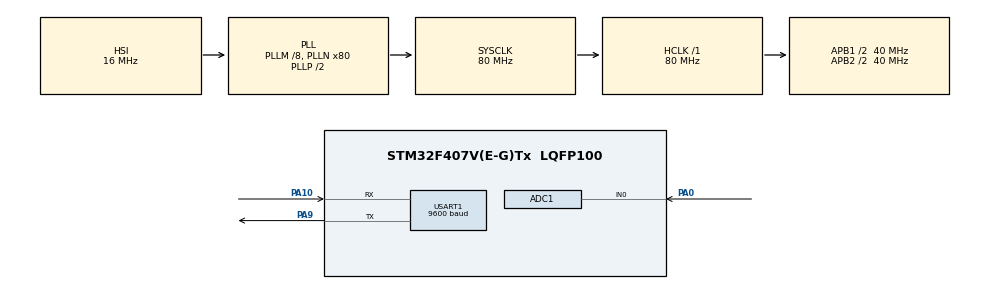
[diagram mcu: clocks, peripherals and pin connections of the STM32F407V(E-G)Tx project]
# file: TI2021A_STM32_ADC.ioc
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ADC1.Channel-0\#ChannelRegularConversion=ADC_CHANNEL_0
ADC1.ContinuousConvMode=ENABLE
ADC1.DMAContinuousRequests=ENABLE
ADC1.NbrOfConversionFlag=1
ADC1.Rank-0\#ChannelRegularConversion=1
ADC1.SamplingTime-0\#ChannelRegularConversion=ADC_SAMPLETIME_3CYCLES
ADC1.master=1
Dma.ADC1.0.Direction=DMA_PERIPH_TO_MEMORY
Dma.ADC1.0.FIFOMode=DMA_FIFOMODE_DISABLE
Dma.ADC1.0.Instance=DMA2_Stream0
Dma.ADC1.0.MemDataAlignment=DMA_MDATAALIGN_WORD
Dma.ADC1.0.MemInc=DMA_MINC_ENABLE
Dma.ADC1.0.Mode=DMA_CIRCULAR
Dma.ADC1.0.PeriphDataAlignment=DMA_PDATAALIGN_WORD
Dma.ADC1.0.PeriphInc=DMA_PINC_DISABLE
Dma.ADC1.0.Priority=DMA_PRIORITY_LOW
Dma.Request0=ADC1
Mcu.Family=STM32F4
Mcu.Name=STM32F407V(E-G)Tx
Mcu.Package=LQFP100
NVIC.DMA2_Stream0_IRQn=true\:0\:0\:false\:false\:true\:false\:true\:true
NVIC.PriorityGroup=NVIC_PRIORITYGROUP_4
NVIC.USART1_IRQn=true\:0\:0\:false\:false\:true\:true\:true\:true
PA0-WKUP.Signal=ADCx_IN0
PA10.Mode=Asynchronous
PA10.Signal=USART1_RX
PA13.Mode=Serial_Wire
PA13.Signal=SYS_JTMS-SWDIO
PA14.Mode=Serial_Wire
PA14.Signal=SYS_JTCK-SWCLK
PA9.Mode=Asynchronous
PA9.Signal=USART1_TX
ProjectManager.HeapSize=0x200
ProjectManager.StackSize=0x400
ProjectManager.TargetToolchain=MDK-ARM V5.32
RCC.48MHZClocksFreq_Value=40000000
RCC.AHBFreq_Value=80000000
RCC.APB1CLKDivider=RCC_HCLK_DIV2
RCC.APB1Freq_Value=40000000
RCC.APB1TimFreq_Value=80000000
RCC.APB2CLKDivider=RCC_HCLK_DIV2
RCC.APB2Freq_Value=40000000
RCC.APB2TimFreq_Value=80000000
RCC.CortexFreq_Value=80000000
RCC.HCLKFreq_Value=80000000
RCC.HSE_VALUE=25000000
RCC.HSI_VALUE=16000000
RCC.PLLM=8
RCC.PLLN=80
RCC.SYSCLKFreq_VALUE=80000000
RCC.SYSCLKSource=RCC_SYSCLKSOURCE_PLLCLK
RCC.VCOOutputFreq_Value=160000000
SH.ADCx_IN0.0=ADC1_IN0,IN0
USART1.BaudRate=9600
USART1.VirtualMode=VM_ASYNC
board=custom

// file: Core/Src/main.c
/* USER CODE BEGIN Header */
/**
  ******************************************************************************
  * @file           : main.c
  * @brief          : Main program body
  ******************************************************************************
  * @attention
  *
  * Copyright (c) 2023 STMicroelectronics.
  * All rights reserved.
  *
  * This software is licensed under terms that can be found in the LICENSE file
  * in the root directory of this software component.
  * If no LICENSE file comes with this software, it is provided AS-IS.
  *
  ******************************************************************************
  */
/* USER CODE END Header */
#include "main.h"
#include "adc.h"
#include "dma.h"
#include "usart.h"
#include "gpio.h"
#include <string.h>

/* USER CODE BEGIN Includes */
#define UART_RX_BUF_SIZE 1024
/* USER CODE END Includes */

/* USER CODE BEGIN PV */
static char uart1_rx_bp[UART_RX_BUF_SIZE];
static char uart1_tx_bp[UART_RX_BUF_SIZE];
static uint8_t uart1_rx_cnt = 0;
static uint8_t uart1_tx_cnt = 0;
static uint8_t uart1_rx_buf = 0;
// static uint8_t uart1_tx_buf = 0;
static int adc_freq = 0;
/* USER CODE END PV */

void SystemClock_Config(void);

int main(void)
{

  /* MCU Configuration--------------------------------------------------------*/

  /* Reset of all peripherals, Initializes the Flash interface and the Systick. */
	HAL_Init();

  /* Configure the system clock */
	SystemClock_Config();

  /* Initialize all configured peripherals */
	MX_GPIO_Init();
	MX_DMA_Init();
	MX_ADC1_Init();
	MX_USART1_UART_Init();
  /* USER CODE BEGIN 2 */
	HAL_UART_Receive_IT(&huart1, (uint8_t *)&uart1_rx_buf, 1);
  /* USER CODE END 2 */

  /* Infinite loop */
  while (1)
  {

  }
}

void SystemClock_Config(void)
{
  RCC_OscInitTypeDef RCC_OscInitStruct = {0};
  RCC_ClkInitTypeDef RCC_ClkInitStruct = {0};

  /** Configure the main internal regulator output voltage
  */
  __HAL_RCC_PWR_CLK_ENABLE();
  __HAL_PWR_VOLTAGESCALING_CONFIG(PWR_REGULATOR_VOLTAGE_SCALE1);

  /** Initializes the RCC Oscillators according to the specified parameters
  * in the RCC_OscInitTypeDef structure.
  */
  RCC_OscInitStruct.OscillatorType = RCC_OSCILLATORTYPE_HSI;
  RCC_OscInitStruct.HSIState = RCC_HSI_ON;
  RCC_OscInitStruct.HSICalibrationValue = RCC_HSICALIBRATION_DEFAULT;
  RCC_OscInitStruct.PLL.PLLState = RCC_PLL_ON;
  RCC_OscInitStruct.PLL.PLLSource = RCC_PLLSOURCE_HSI;
  RCC_OscInitStruct.PLL.PLLM = 8;
  RCC_OscInitStruct.PLL.PLLN = 80;
  RCC_OscInitStruct.PLL.PLLP = RCC_PLLP_DIV2;
  RCC_OscInitStruct.PLL.PLLQ = 4;
  if (HAL_RCC_OscConfig(&RCC_OscInitStruct) != HAL_OK)
  {
    Error_Handler();
  }

  /** Initializes the CPU, AHB and APB buses clocks
  */
  RCC_ClkInitStruct.ClockType = RCC_CLOCKTYPE_HCLK|RCC_CLOCKTYPE_SYSCLK
                              |RCC_CLOCKTYPE_PCLK1|RCC_CLOCKTYPE_PCLK2;
  RCC_ClkInitStruct.SYSCLKSource = RCC_SYSCLKSOURCE_PLLCLK;
  RCC_ClkInitStruct.AHBCLKDivider = RCC_SYSCLK_DIV1;
  RCC_ClkInitStruct.APB1CLKDivider = RCC_HCLK_DIV2;
  RCC_ClkInitStruct.APB2CLKDivider = RCC_HCLK_DIV2;

  if (HAL_RCC_ClockConfig(&RCC_ClkInitStruct, FLASH_LATENCY_2) != HAL_OK)
  {
    Error_Handler();
  }
}

/* USER CODE BEGIN 4 */

void UART_RX_Data_Parse(char* p, uint8_t cnt)
{
	adc_freq = 0;
	for (int i = 0; i < 4; ++i)
	{
		adc_freq += ((p[i] & 0xff) << (8 * i));
	}
	memset(uart1_tx_bp, 0x00, sizeof(uart1_tx_bp));
	uart1_tx_cnt = 7;
	for (int i = 0; i < sizeof(int); ++i)
    {
        uart1_tx_bp[i] = ((adc_freq >> (i * 8))) & 0xff;
    }
	for (int i = 4; i < uart1_tx_cnt; ++i)
	{
		uart1_tx_bp[i] = 0xff;
	}
}

void HAL_UART_RxCpltCallback(UART_HandleTypeDef *huart)
{
	/* Prevent unused argument(s) compilation warning */
	UNUSED(huart);

	if(uart1_rx_cnt >= UART_RX_BUF_SIZE)  //溢出判断
	{
		uart1_rx_cnt = 0;
		memset(uart1_rx_bp, 0x00, sizeof(uart1_rx_bp));
		HAL_UART_Transmit(&huart1, (uint8_t *)"OVERFLOW!!!", 12, 0xFFFF);

	}
	else
	{
		uart1_rx_bp[uart1_rx_cnt++] = uart1_rx_buf;   //接收数据转存

		if((uart1_rx_cnt > 3)&&(uart1_rx_bp[uart1_rx_cnt-1] == 0xFF)&&(uart1_rx_bp[uart1_rx_cnt-2] == 0xFF)&&(uart1_rx_bp[uart1_rx_cnt-3] == 0xFF)) //判断结束位
		{
			UART_RX_Data_Parse(uart1_rx_bp, uart1_rx_cnt);
			HAL_UART_Transmit(&huart1, (uint8_t *)&uart1_tx_bp, uart1_tx_cnt, 0xFFFF); //将收到的信息发送出去
            while(HAL_UART_GetState(&huart1) == HAL_UART_STATE_BUSY_TX);
			uart1_rx_cnt = 0;
			memset(uart1_rx_bp, 0x00, sizeof(uart1_rx_bp)); //清空数组
		}
	}

	HAL_UART_Receive_IT(&huart1, (uint8_t *)&uart1_rx_buf, 1);   //再开启接收中断
}
/* USER CODE END 4 */

void Error_Handler(void)
{
  __disable_irq();
  while (1)
  {
  }
}
